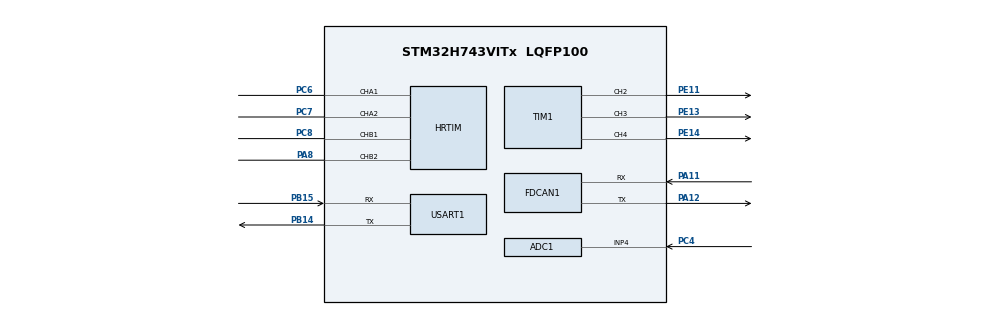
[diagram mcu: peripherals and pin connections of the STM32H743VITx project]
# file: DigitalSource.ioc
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ADC1.Channel-1\#ChannelRegularConversion=ADC_CHANNEL_4
ADC1.ContinuousConvMode=ENABLE
ADC1.ConversionDataManagement=ADC_CONVERSIONDATA_DMA_CIRCULAR
ADC1.NbrOfConversion=1
ADC1.NbrOfConversionFlag=1
ADC1.OffsetNumber-1\#ChannelRegularConversion=ADC_OFFSET_NONE
ADC1.OffsetSignedSaturation-1\#ChannelRegularConversion=DISABLE
ADC1.OversamplingMode=ENABLE
ADC1.Rank-1\#ChannelRegularConversion=1
ADC1.Ratio=8
ADC1.RightBitShift=ADC_RIGHTBITSHIFT_3
ADC1.SamplingTime-1\#ChannelRegularConversion=ADC_SAMPLETIME_1CYCLE_5
ADC1.master=1
Dma.ADC1.0.Direction=DMA_PERIPH_TO_MEMORY
Dma.ADC1.0.EventEnable=DISABLE
Dma.ADC1.0.FIFOMode=DMA_FIFOMODE_DISABLE
Dma.ADC1.0.Instance=DMA1_Stream0
Dma.ADC1.0.MemDataAlignment=DMA_MDATAALIGN_HALFWORD
Dma.ADC1.0.MemInc=DMA_MINC_ENABLE
Dma.ADC1.0.Mode=DMA_CIRCULAR
Dma.ADC1.0.PeriphDataAlignment=DMA_PDATAALIGN_HALFWORD
Dma.ADC1.0.PeriphInc=DMA_PINC_DISABLE
Dma.ADC1.0.Polarity=HAL_DMAMUX_REQ_GEN_RISING
Dma.ADC1.0.Priority=DMA_PRIORITY_LOW
Dma.ADC1.0.RequestNumber=1
Dma.ADC1.0.SignalID=NONE
Dma.ADC1.0.SyncEnable=DISABLE
Dma.ADC1.0.SyncPolarity=HAL_DMAMUX_SYNC_NO_EVENT
Dma.ADC1.0.SyncRequestNumber=1
Dma.ADC1.0.SyncSignalID=NONE
Dma.Request0=ADC1
FDCAN1.CalculateBaudRateNominal=937499
FDCAN1.CalculateTimeBitNominal=1066
FDCAN1.CalculateTimeQuantumNominal=213.33333333333334
HRTIM.CompareUnit1-Output_TA1TA2=HRTIM_COMPAREUNIT_1
HRTIM.CompareUnit1-Output_TB1TB2=HRTIM_COMPAREUNIT_1
HRTIM.CompareValue1-Output_TA1TA2=1000
HRTIM.CompareValue1-Output_TB1TB2=1000
HRTIM.DeadTimeInsertion-Output_TA1TA2=HRTIM_TIMDEADTIMEINSERTION_ENABLED
HRTIM.DeadTimeInsertion-Output_TB1TB2=HRTIM_TIMDEADTIMEINSERTION_ENABLED
HRTIM.FallingValue-Output_TA1TA2=100
HRTIM.FallingValue-Output_TB1TB2=100
HRTIM.NumberInterruptRequests_Master-MasterTimer=0
HRTIM.NumberResetSource1-Output_TA1TA2=1
HRTIM.NumberResetSource1-Output_TB1TB2=1
HRTIM.NumberResetTrigger-Output_TA1TA2=1
HRTIM.NumberResetTrigger-Output_TB1TB2=1
HRTIM.NumberSetSource1-Output_TA1TA2=1
HRTIM.NumberSetSource1-Output_TB1TB2=1
HRTIM.Periode_MASTER=4800
HRTIM.Periode_TA=4800
HRTIM.Periode_TB=4800
HRTIM.PreloadEnable-Output_TA1TA2=HRTIM_PRELOAD_ENABLED
HRTIM.PreloadEnable-Output_TB1TB2=HRTIM_PRELOAD_ENABLED
HRTIM.PrescalerDead-Output_TA1TA2=HRTIM_TIMDEADTIME_PRESCALERRATIO_DIV1
HRTIM.PrescalerDead-Output_TB1TB2=HRTIM_TIMDEADTIME_PRESCALERRATIO_DIV1
HRTIM.RepetitionUpdate-Output_TA1TA2=HRTIM_UPDATEONREPETITION_ENABLED
HRTIM.RepetitionUpdate-Output_TB1TB2=HRTIM_UPDATEONREPETITION_ENABLED
HRTIM.ResetOutput1_Source1-Output_TA1TA2=HRTIM_OUTPUTRESET_MASTERPER
HRTIM.ResetOutput1_Source1-Output_TB1TB2=HRTIM_OUTPUTRESET_MASTERPER
HRTIM.ResetTrigger1-Output_TA1TA2=HRTIM_TIMRESETTRIGGER_MASTER_PER
HRTIM.ResetTrigger1-Output_TB1TB2=HRTIM_TIMRESETTRIGGER_MASTER_PER
HRTIM.ResetUpdate-Output_TA1TA2=HRTIM_TIMUPDATEONRESET_ENABLED
HRTIM.ResetUpdate-Output_TB1TB2=HRTIM_TIMUPDATEONRESET_ENABLED
HRTIM.RisingValue-Output_TA1TA2=100
HRTIM.RisingValue-Output_TB1TB2=100
HRTIM.SetOutput1_Source1-Output_TA1TA2=HRTIM_OUTPUTSET_TIMCMP1
HRTIM.SetOutput1_Source1-Output_TB1TB2=HRTIM_OUTPUTSET_TIMCMP1
Mcu.Family=STM32H7
Mcu.Name=STM32H743VITx
Mcu.Package=LQFP100
NVIC.PriorityGroup=NVIC_PRIORITYGROUP_2
NVIC.TIM7_IRQn=true\:0\:0\:false\:false\:true\:true\:true\:true
NVIC.USART1_IRQn=true\:2\:1\:true\:false\:true\:true\:true\:true
PA11.Mode=FDCAN_Activate
PA11.Signal=FDCAN1_RX
PA12.Mode=FDCAN_Activate
PA12.Signal=FDCAN1_TX
PA8.Mode=Output_TB1TB2
PA8.Signal=HRTIM_CHB2
PB14.Mode=Asynchronous
PB14.Signal=USART1_TX
PB15.Mode=Asynchronous
PB15.Signal=USART1_RX
PC14-OSC32_IN\ (OSC32_IN).Mode=LSE-External-Oscillator
PC14-OSC32_IN\ (OSC32_IN).Signal=RCC_OSC32_IN
PC15-OSC32_OUT\ (OSC32_OUT).Mode=LSE-External-Oscillator
PC15-OSC32_OUT\ (OSC32_OUT).Signal=RCC_OSC32_OUT
PC4.Signal=ADCx_INP4
PC6.Mode=Output_TA1TA2
PC6.Signal=HRTIM_CHA1
PC7.Mode=Output_TA1TA2
PC7.Signal=HRTIM_CHA2
PC8.Mode=Output_TB1TB2
PC8.Signal=HRTIM_CHB1
PE11.Signal=S_TIM1_CH2
PE13.Signal=S_TIM1_CH3
PE14.Signal=S_TIM1_CH4
PH0-OSC_IN\ (PH0).Mode=HSE-External-Oscillator
PH0-OSC_IN\ (PH0).Signal=RCC_OSC_IN
PH1-OSC_OUT\ (PH1).Mode=HSE-External-Oscillator
PH1-OSC_OUT\ (PH1).Signal=RCC_OSC_OUT
ProjectManager.HeapSize=0x200
ProjectManager.StackSize=0x400
ProjectManager.TargetToolchain=MDK-ARM V5.32
RCC.ADCFreq_Value=75000000
RCC.APB1Freq_Value=120000000
RCC.APB2Freq_Value=120000000
RCC.APB3Freq_Value=120000000
RCC.APB4Freq_Value=120000000
RCC.CortexFreq_Value=480000000
RCC.D1PPRE=RCC_APB3_DIV2
RCC.D2PPRE1=RCC_APB1_DIV2
RCC.D2PPRE2=RCC_APB2_DIV2
RCC.D3PPRE=RCC_APB4_DIV2
RCC.DIVM1=5
RCC.DIVM2=2
RCC.DIVN1=192
RCC.DIVN2=12
RCC.FDCANCLockSelection=RCC_FDCANCLKSOURCE_PLL2
RCC.HCLKFreq_Value=240000000
RCC.HPRE=RCC_HCLK_DIV2
RCC.HRTIMCLockSelection=RCC_HRTIM1CLK_CPUCLK
RCC.PLLFRACN=0
RCC.PLLSourceVirtual=RCC_PLLSOURCE_HSE
RCC.SYSCLKFreq_VALUE=480000000
RCC.SYSCLKSource=RCC_SYSCLKSOURCE_PLLCLK
RCC.USBFreq_Value=480000000
SH.ADCx_INP4.0=ADC1_INP4,IN4-Single-Ended
SH.ADCx_INP4.1=ADC2_INP4
SH.S_TIM1_CH2.0=TIM1_CH2,PWM Generation2 CH2
SH.S_TIM1_CH3.0=TIM1_CH3,PWM Generation3 CH3
SH.S_TIM1_CH4.0=TIM1_CH4,PWM Generation4 CH4
TIM1.Channel-PWM\ Generation2\ CH2=TIM_CHANNEL_2
TIM1.Channel-PWM\ Generation3\ CH3=TIM_CHANNEL_3
TIM1.Channel-PWM\ Generation4\ CH4=TIM_CHANNEL_4
USART1.VirtualMode-Asynchronous=VM_ASYNC
VP_HRTIM_VS_hrtimMasterTimerNoOutput.Mode=MasterTimer
VP_TIM7_VS_ClockSourceINT.Mode=Enable_Timer
board=custom

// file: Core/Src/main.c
/* USER CODE BEGIN Header */
/**
  ******************************************************************************
  * @file           : main.c
  * @brief          : Main program body
  ******************************************************************************
  * @attention
  *
  * Copyright (c) 2024 STMicroelectronics.
  * All rights reserved.
  *
  * This software is licensed under terms that can be found in the LICENSE file
  * in the root directory of this software component.
  * If no LICENSE file comes with this software, it is provided AS-IS.
  *
  ******************************************************************************
  */
/* USER CODE END Header */
#include "main.h"
#include "adc.h"
#include "dma.h"
#include "fdcan.h"
#include "hrtim.h"
#include "tim.h"
#include "usart.h"
#include "gpio.h"

/* USER CODE BEGIN Includes */
#include "flash_bsp.h"
#include "Config.h"
#include "UpperComputer.h"
/* USER CODE END Includes */

void SystemClock_Config(void);
void PeriphCommonClock_Config(void);

/* USER CODE BEGIN 0 */
double measure = 0;
double target = 5.0;
double buck_duty = 0;
double boost_duty = 0;
extern FlashBsp_t myflash;
/* USER CODE END 0 */

int main(void)
{

  /* MCU Configuration--------------------------------------------------------*/

  /* Reset of all peripherals, Initializes the Flash interface and the Systick. */
  HAL_Init();

  /* Configure the system clock */
  SystemClock_Config();

/* Configure the peripherals common clocks */
  PeriphCommonClock_Config();

  /* Initialize all configured peripherals */
  MX_GPIO_Init();
  MX_DMA_Init();
  MX_FDCAN1_Init();
  MX_HRTIM_Init();
  MX_USART1_UART_Init();
  MX_ADC1_Init();
  MX_TIM1_Init();
  MX_TIM7_Init();

  /* USER CODE BEGIN 2 */

  Control_Init();
  //UpperComputer_Init();

  /* USER CODE END 2 */

  /* Infinite loop */
  while (1)
  {

  }
}

void SystemClock_Config(void)
{
  RCC_OscInitTypeDef RCC_OscInitStruct = {0};
  RCC_ClkInitTypeDef RCC_ClkInitStruct = {0};

  /** Supply configuration update enable
  */
  HAL_PWREx_ConfigSupply(PWR_LDO_SUPPLY);

  /** Configure the main internal regulator output voltage
  */
  __HAL_PWR_VOLTAGESCALING_CONFIG(PWR_REGULATOR_VOLTAGE_SCALE1);

  while(!__HAL_PWR_GET_FLAG(PWR_FLAG_VOSRDY)) {}

  __HAL_RCC_SYSCFG_CLK_ENABLE();
  __HAL_PWR_VOLTAGESCALING_CONFIG(PWR_REGULATOR_VOLTAGE_SCALE0);

  while(!__HAL_PWR_GET_FLAG(PWR_FLAG_VOSRDY)) {}

  /** Initializes the RCC Oscillators according to the specified parameters
  * in the RCC_OscInitTypeDef structure.
  */
  RCC_OscInitStruct.OscillatorType = RCC_OSCILLATORTYPE_HSE;
  RCC_OscInitStruct.HSEState = RCC_HSE_ON;
  RCC_OscInitStruct.PLL.PLLState = RCC_PLL_ON;
  RCC_OscInitStruct.PLL.PLLSource = RCC_PLLSOURCE_HSE;
  RCC_OscInitStruct.PLL.PLLM = 5;
  RCC_OscInitStruct.PLL.PLLN = 192;
  RCC_OscInitStruct.PLL.PLLP = 2;
  RCC_OscInitStruct.PLL.PLLQ = 2;
  RCC_OscInitStruct.PLL.PLLR = 2;
  RCC_OscInitStruct.PLL.PLLRGE = RCC_PLL1VCIRANGE_2;
  RCC_OscInitStruct.PLL.PLLVCOSEL = RCC_PLL1VCOWIDE;
  RCC_OscInitStruct.PLL.PLLFRACN = 0;
  if (HAL_RCC_OscConfig(&RCC_OscInitStruct) != HAL_OK)
  {
    Error_Handler();
  }

  /** Initializes the CPU, AHB and APB buses clocks
  */
  RCC_ClkInitStruct.ClockType = RCC_CLOCKTYPE_HCLK|RCC_CLOCKTYPE_SYSCLK
                              |RCC_CLOCKTYPE_PCLK1|RCC_CLOCKTYPE_PCLK2
                              |RCC_CLOCKTYPE_D3PCLK1|RCC_CLOCKTYPE_D1PCLK1;
  RCC_ClkInitStruct.SYSCLKSource = RCC_SYSCLKSOURCE_PLLCLK;
  RCC_ClkInitStruct.SYSCLKDivider = RCC_SYSCLK_DIV1;
  RCC_ClkInitStruct.AHBCLKDivider = RCC_HCLK_DIV2;
  RCC_ClkInitStruct.APB3CLKDivider = RCC_APB3_DIV2;
  RCC_ClkInitStruct.APB1CLKDivider = RCC_APB1_DIV2;
  RCC_ClkInitStruct.APB2CLKDivider = RCC_APB2_DIV2;
  RCC_ClkInitStruct.APB4CLKDivider = RCC_APB4_DIV2;

  if (HAL_RCC_ClockConfig(&RCC_ClkInitStruct, FLASH_LATENCY_4) != HAL_OK)
  {
    Error_Handler();
  }
}

void PeriphCommonClock_Config(void)
{
  RCC_PeriphCLKInitTypeDef PeriphClkInitStruct = {0};

  /** Initializes the peripherals clock
  */
  PeriphClkInitStruct.PeriphClockSelection = RCC_PERIPHCLK_ADC|RCC_PERIPHCLK_FDCAN;
  PeriphClkInitStruct.PLL2.PLL2M = 2;
  PeriphClkInitStruct.PLL2.PLL2N = 12;
  PeriphClkInitStruct.PLL2.PLL2P = 2;
  PeriphClkInitStruct.PLL2.PLL2Q = 2;
  PeriphClkInitStruct.PLL2.PLL2R = 2;
  PeriphClkInitStruct.PLL2.PLL2RGE = RCC_PLL2VCIRANGE_3;
  PeriphClkInitStruct.PLL2.PLL2VCOSEL = RCC_PLL2VCOMEDIUM;
  PeriphClkInitStruct.PLL2.PLL2FRACN = 0;
  PeriphClkInitStruct.FdcanClockSelection = RCC_FDCANCLKSOURCE_PLL2;
  PeriphClkInitStruct.AdcClockSelection = RCC_ADCCLKSOURCE_PLL2;
  if (HAL_RCCEx_PeriphCLKConfig(&PeriphClkInitStruct) != HAL_OK)
  {
    Error_Handler();
  }
}

void Error_Handler(void)
{
  __disable_irq();
  while (1)
  {
  }
}
